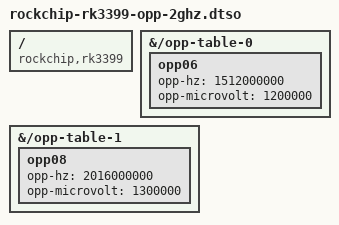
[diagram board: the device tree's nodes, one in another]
/dts-v1/;
/plugin/;

/ {
	compatible = "rockchip,rk3399";
};

&{/opp-table-0} {
	opp06 {
		opp-hz = /bits/ 64 <1512000000>;
		opp-microvolt = <1200000>;
	};
};

&{/opp-table-1} {
	opp08 {
		opp-hz = /bits/ 64 <2016000000>;
		opp-microvolt = <1300000>;
	};
};
